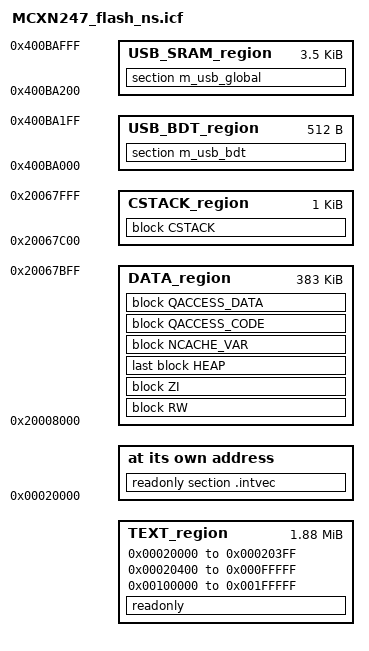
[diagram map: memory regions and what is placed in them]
/*
** ###################################################################
**     Processors:          MCXN247VAB_cm33_core0
**                          MCXN247VDF_cm33_core0
**                          MCXN247VKL_cm33_core0
**                          MCXN247VPB_cm33_core0
**
**     Compiler:            IAR ANSI C/C++ Compiler for ARM
**     Reference manual:    MCXNx4x Reference Manual
**     Version:             rev. 1.0, 2021-08-03
**     Build:               b250709
**
**     Abstract:
**         Linker file for the IAR ANSI C/C++ Compiler for ARM
**
**     Copyright 2016 Freescale Semiconductor, Inc.
**     Copyright 2016-2025 NXP
**     SPDX-License-Identifier: BSD-3-Clause
**
**     http:                 www.nxp.com
**     mail:                 support@nxp.com
**
** ###################################################################
*/


/* USB BDT size */
define symbol usb_bdt_size             = 0x200;
/* Stack and Heap Sizes */
if (isdefinedsymbol(__stack_size__)) {
  define symbol __size_cstack__        = __stack_size__;
} else {
  define symbol __size_cstack__        = 0x0400;
}

if (isdefinedsymbol(__heap_size__)) {
  define symbol __size_heap__          = __heap_size__;
} else {
  define symbol __size_heap__          = 0x0400;
}

define symbol m_interrupts_start               = 0x00020000;
define symbol m_interrupts_end                 = 0x000203FF;

define symbol m_text_start                     = 0x00020400;
define symbol m_text_end                       = 0x000FFFFF;

define symbol m_flash1_start                   = 0x00100000;
define symbol m_flash1_end                     = 0x001FFFFF;

define symbol m_sramx_start                    = 0x04000000;
define symbol m_sramx_end                      = 0x04017FFF;

define symbol m_data_start                     = 0x20008000;
define symbol m_data_end                       = 0x20067FFF;

define symbol m_usb_sram_start                 = 0x400BA000;
define symbol m_usb_sram_end                   = 0x400BAFFF;


define memory mem with size = 4G;

define region TEXT_region             = mem:[from m_interrupts_start to m_interrupts_end]
                                      | mem:[from m_text_start to m_text_end]
                                      | mem:[from m_flash1_start to m_flash1_end];
define region DATA_region = mem:[from m_data_start to m_data_end-__size_cstack__];
define region CSTACK_region = mem:[from m_data_end-__size_cstack__+1 to m_data_end];


define block CSTACK        with alignment = 8, size = __size_cstack__   { };
define block HEAP          with alignment = 8, size = __size_heap__     { };
define block RW            { readwrite };
define block ZI            { zi };
define block NCACHE_VAR    { section NonCacheable , section NonCacheable.init };
define block QACCESS_CODE  { section CodeQuickAccess };
define block QACCESS_DATA  { section DataQuickAccess };

/* regions for USB */
define region USB_BDT_region = mem:[from m_usb_sram_start to m_usb_sram_start + usb_bdt_size - 1];
define region USB_SRAM_region = mem:[from m_usb_sram_start + usb_bdt_size to m_usb_sram_end];
place in USB_BDT_region                     { section m_usb_bdt };
place in USB_SRAM_region                    { section m_usb_global };

initialize by copy { readwrite, section .textrw, section CodeQuickAccess, section DataQuickAccess };

if (isdefinedsymbol(__USE_DLIB_PERTHREAD))
{
  /* Required in a multi-threaded application */
  initialize by copy with packing = none { section __DLIB_PERTHREAD };
}

do not initialize  { section .noinit, section m_usb_bdt, section m_usb_global };
place at address mem: m_interrupts_start    { readonly section .intvec };
place in TEXT_region                        { readonly };
place in DATA_region                        { block RW };
place in DATA_region                        { block ZI };
place in DATA_region                        { last block HEAP };
place in CSTACK_region                      { block CSTACK };
place in DATA_region                        { block NCACHE_VAR };
place in DATA_region                        { block QACCESS_CODE };
place in DATA_region                        { block QACCESS_DATA };

